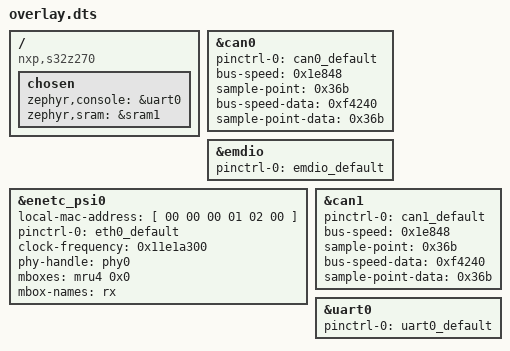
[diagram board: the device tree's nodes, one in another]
/ {
	compatible = "nxp,s32z270";
	chosen {
		zephyr,console = &uart0;
		zephyr,sram = &sram1;
	};
};
&can0{
	status = "okay";
	pinctrl-0 = < &can0_default >;
	pinctrl-names = "default";
	bus-speed = < 0x1e848 >;
	sample-point = < 0x36b >;
	bus-speed-data = < 0xf4240 >;
	sample-point-data = < 0x36b >;
};
&emdio{
	status = "okay";
	pinctrl-0 = < &emdio_default >;
	pinctrl-names = "default";
};
&enetc_psi0{
	status = "okay";
	local-mac-address = [ 00 00 00 01 02 00 ];
	pinctrl-0 = < &eth0_default >;
	pinctrl-names = "default";
	clock-frequency = < 0x11e1a300 >;
	phy-handle = < &phy0 >;
	mboxes = < &mru4 0x0 >;
	mbox-names = "rx";
};
&can1{
	pinctrl-0 = < &can1_default >;
	pinctrl-names = "default";
	bus-speed = < 0x1e848 >;
	sample-point = < 0x36b >;
	bus-speed-data = < 0xf4240 >;
	sample-point-data = < 0x36b >;
};
&uart0{
	status = "okay";
	pinctrl-0 = < &uart0_default >;
	pinctrl-names = "default";
};
